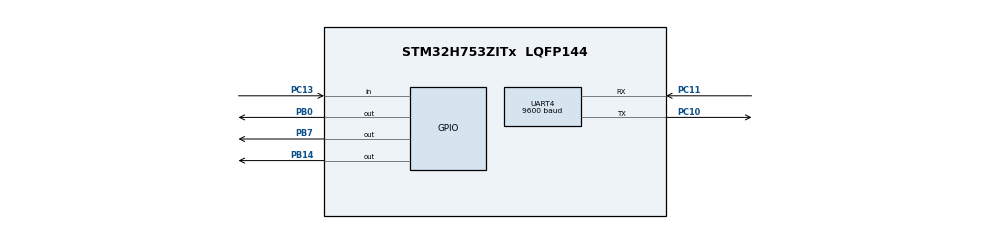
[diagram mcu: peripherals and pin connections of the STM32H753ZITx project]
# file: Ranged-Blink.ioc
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CORTEX_M7.CPU_DCache=Disabled
CORTEX_M7.CPU_ICache=Disabled
CORTEX_M7.MPU_Control=__NULL
CORTEX_M7.default_mode_Activation=1
Mcu.Family=STM32H7
Mcu.Name=STM32H753ZITx
Mcu.Package=LQFP144
NUCLEO-H753ZI.BUTTON=1
NUCLEO-H753ZI.Bsp_Common_DEMO=true
NUCLEO-H753ZI.LD1=true
NUCLEO-H753ZI.LD2=true
NUCLEO-H753ZI.LD3=true
NUCLEO-H753ZI.VCP=true
NVIC.EXTI15_10_IRQn=true\:0\:0\:false\:false\:true\:false\:true\:true
NVIC.PriorityGroup=NVIC_PRIORITYGROUP_4
PB0.Signal=GPIO_Output
PB14.Signal=GPIO_Output
PB7.Signal=GPIO_Output
PC10.Mode=Asynchronous
PC10.Signal=UART4_TX
PC11.Mode=Asynchronous
PC11.Signal=UART4_RX
PC13.Signal=GPIO_Input
PC14-OSC32_IN\ (OSC32_IN).Signal=RCC_OSC32_IN
PC15-OSC32_OUT\ (OSC32_OUT).Signal=RCC_OSC32_OUT
PD8.Signal=USART3_TX
PD9.Signal=USART3_RX
PH0-OSC_IN\ (PH0).Signal=RCC_OSC_IN
PH1-OSC_OUT\ (PH1).Signal=RCC_OSC_OUT
ProjectManager.HeapSize=0x200
ProjectManager.StackSize=0x400
ProjectManager.TargetToolchain=STM32CubeIDE
RCC.ADCFreq_Value=129000000
RCC.APB1Freq_Value=64000000
RCC.APB2Freq_Value=64000000
RCC.APB3Freq_Value=64000000
RCC.APB4Freq_Value=64000000
RCC.CortexFreq_Value=64000000
RCC.DIVM1=1
RCC.DIVN1=24
RCC.DIVQ1=4
RCC.HCLKFreq_Value=64000000
RCC.HSE_VALUE=8000000
RCC.PLLFRACN=0
RCC.PWR_Regulator_Voltage_Scale=PWR_REGULATOR_VOLTAGE_SCALE2
RCC.SYSCLKFreq_VALUE=64000000
RCC.USBFreq_Value=384000000
UART4.BaudRate=9600
VP_MEMORYMAP_VS_MEMORYMAP.Mode=CurAppReg
VP_NUCLEO-H753ZI_VS_BSP_COMMON.Mode=COMMON
board=NUCLEO-H753ZI

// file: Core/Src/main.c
/* USER CODE BEGIN Header */
/**
  ******************************************************************************
  * @file           : main.c
  * @brief          : Main program body
  ******************************************************************************
  * @attention
  *
  * Copyright (c) 2025 STMicroelectronics.
  * All rights reserved.
  *
  * This software is licensed under terms that can be found in the LICENSE file
  * in the root directory of this software component.
  * If no LICENSE file comes with this software, it is provided AS-IS.
  *
  ******************************************************************************
  */
/* USER CODE END Header */
#include "main.h"

COM_InitTypeDef BspCOMInit;
__IO uint32_t BspButtonState = BUTTON_RELEASED;

UART_HandleTypeDef huart4;

void SystemClock_Config(void);
static void MX_GPIO_Init(void);
static void MX_UART4_Init(void);

void HAL_UART_RxCpltCallback(UART_HandleTypeDef *huart){

}

int main(void)
{

  /* MCU Configuration--------------------------------------------------------*/

  /* Reset of all peripherals, Initializes the Flash interface and the Systick. */
  HAL_Init();

  /* Configure the system clock */
  SystemClock_Config();

  /* Initialize all configured peripherals */
  MX_GPIO_Init();
  MX_UART4_Init();

  /* Initialize leds */
  BSP_LED_Init(LED_GREEN);
  BSP_LED_Init(LED_BLUE);
  BSP_LED_Init(LED_RED);

  /* Initialize USER push-button, will be used to trigger an interrupt each time it's pressed.*/
  BSP_PB_Init(BUTTON_USER, BUTTON_MODE_EXTI);

  /* Initialize COM1 port (115200, 8 bits (7-bit data + 1 stop bit), no parity */
  BspCOMInit.BaudRate   = 115200;
  BspCOMInit.WordLength = COM_WORDLENGTH_8B;
  BspCOMInit.StopBits   = COM_STOPBITS_1;
  BspCOMInit.Parity     = COM_PARITY_NONE;
  BspCOMInit.HwFlowCtl  = COM_HWCONTROL_NONE;
  if (BSP_COM_Init(COM1, &BspCOMInit) != BSP_ERROR_NONE)
  {
    Error_Handler();
  }

  /* USER CODE BEGIN BSP */

  /* -- Sample board code to send message over COM1 port ---- */
  printf("Welcome to STM32 world !\n\r");

  /* -- Sample board code to switch on leds ---- */
  BSP_LED_On(LED_GREEN);
  BSP_LED_On(LED_BLUE);
  BSP_LED_On(LED_RED);

  /* USER CODE END BSP */

  /* Infinite loop */
  /* USER CODE BEGIN WHILE */
  while (1)
  {

    /* -- Sample board code for User push-button in interrupt mode ---- */
    if (BspButtonState == BUTTON_PRESSED)
    {
      /* Update button state */
      BspButtonState = BUTTON_RELEASED;
      /* -- Sample board code to toggle leds ---- */
      BSP_LED_Toggle(LED_GREEN);
      BSP_LED_Toggle(LED_BLUE);
      BSP_LED_Toggle(LED_RED);

      /* ..... Perform your action ..... */
    }

    char buf[16];
    strcpy(buf, "Hello, world!\t\n");
    HAL_UART_Transmit(&huart4, (uint8_t*) buf, 16, HAL_MAX_DELAY);
    HAL_Delay(2000);
    /* USER CODE END WHILE */

    /* USER CODE BEGIN 3 */
  }

  // periodically send data:

  HAL_UART_Transmit_DMA(&huart4, (uint8_t*) buf, 16, HAL_MAX_DELAY);

  /* USER CODE END 3 */
}

void SystemClock_Config(void)
{
  RCC_OscInitTypeDef RCC_OscInitStruct = {0};
  RCC_ClkInitTypeDef RCC_ClkInitStruct = {0};

  /** Supply configuration update enable
  */
  HAL_PWREx_ConfigSupply(PWR_LDO_SUPPLY);

  /** Configure the main internal regulator output voltage
  */
  __HAL_PWR_VOLTAGESCALING_CONFIG(PWR_REGULATOR_VOLTAGE_SCALE2);

  while(!__HAL_PWR_GET_FLAG(PWR_FLAG_VOSRDY)) {}

  /** Initializes the RCC Oscillators according to the specified parameters
  * in the RCC_OscInitTypeDef structure.
  */
  RCC_OscInitStruct.OscillatorType = RCC_OSCILLATORTYPE_HSI;
  RCC_OscInitStruct.HSIState = RCC_HSI_DIV1;
  RCC_OscInitStruct.HSICalibrationValue = RCC_HSICALIBRATION_DEFAULT;
  RCC_OscInitStruct.PLL.PLLState = RCC_PLL_NONE;
  if (HAL_RCC_OscConfig(&RCC_OscInitStruct) != HAL_OK)
  {
    Error_Handler();
  }

  /** Initializes the CPU, AHB and APB buses clocks
  */
  RCC_ClkInitStruct.ClockType = RCC_CLOCKTYPE_HCLK|RCC_CLOCKTYPE_SYSCLK
                              |RCC_CLOCKTYPE_PCLK1|RCC_CLOCKTYPE_PCLK2
                              |RCC_CLOCKTYPE_D3PCLK1|RCC_CLOCKTYPE_D1PCLK1;
  RCC_ClkInitStruct.SYSCLKSource = RCC_SYSCLKSOURCE_HSI;
  RCC_ClkInitStruct.SYSCLKDivider = RCC_SYSCLK_DIV1;
  RCC_ClkInitStruct.AHBCLKDivider = RCC_HCLK_DIV1;
  RCC_ClkInitStruct.APB3CLKDivider = RCC_APB3_DIV1;
  RCC_ClkInitStruct.APB1CLKDivider = RCC_APB1_DIV1;
  RCC_ClkInitStruct.APB2CLKDivider = RCC_APB2_DIV1;
  RCC_ClkInitStruct.APB4CLKDivider = RCC_APB4_DIV1;

  if (HAL_RCC_ClockConfig(&RCC_ClkInitStruct, FLASH_LATENCY_1) != HAL_OK)
  {
    Error_Handler();
  }
}

static void MX_UART4_Init(void)
{

  huart4.Instance = UART4;
  huart4.Init.BaudRate = 9600;
  huart4.Init.WordLength = UART_WORDLENGTH_8B;
  huart4.Init.StopBits = UART_STOPBITS_1;
  huart4.Init.Parity = UART_PARITY_NONE;
  huart4.Init.Mode = UART_MODE_TX_RX;
  huart4.Init.HwFlowCtl = UART_HWCONTROL_NONE;
  huart4.Init.OverSampling = UART_OVERSAMPLING_16;
  huart4.Init.OneBitSampling = UART_ONE_BIT_SAMPLE_DISABLE;
  huart4.Init.ClockPrescaler = UART_PRESCALER_DIV1;
  huart4.AdvancedInit.AdvFeatureInit = UART_ADVFEATURE_NO_INIT;
  if (HAL_UART_Init(&huart4) != HAL_OK)
  {
    Error_Handler();
  }
  if (HAL_UARTEx_SetTxFifoThreshold(&huart4, UART_TXFIFO_THRESHOLD_1_8) != HAL_OK)
  {
    Error_Handler();
  }
  if (HAL_UARTEx_SetRxFifoThreshold(&huart4, UART_RXFIFO_THRESHOLD_1_8) != HAL_OK)
  {
    Error_Handler();
  }
  if (HAL_UARTEx_DisableFifoMode(&huart4) != HAL_OK)
  {
    Error_Handler();
  }

}

static void MX_GPIO_Init(void)
{

  /* GPIO Ports Clock Enable */
  __HAL_RCC_GPIOC_CLK_ENABLE();
  __HAL_RCC_GPIOH_CLK_ENABLE();

}

/**
  * @brief BSP Push Button callback
  * @param Button Specifies the pressed button
  * @retval None
  */
void BSP_PB_Callback(Button_TypeDef Button)
{
  if (Button == BUTTON_USER)
  {
    BspButtonState = BUTTON_PRESSED;
  }
}

void Error_Handler(void)
{
  __disable_irq();
  while (1)
  {
  }
}
